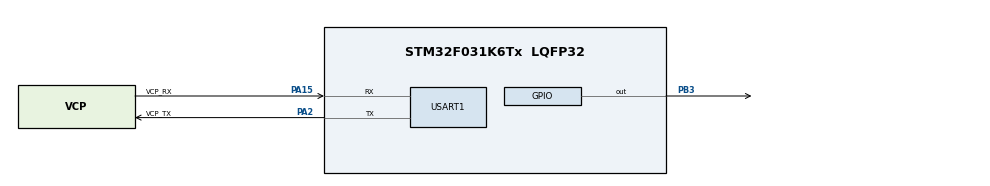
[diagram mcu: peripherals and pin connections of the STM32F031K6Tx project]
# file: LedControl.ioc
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Mcu.Family=STM32F0
Mcu.Name=STM32F031K6Tx
Mcu.Package=LQFP32
NVIC.USART1_IRQn=true\:0\:0\:false\:false\:true\:true\:true
PA13.GPIO_Label=SWDIO
PA13.Mode=Serial_Wire
PA13.Signal=SYS_SWDIO
PA14.GPIO_Label=SWCLK
PA14.Mode=Serial_Wire
PA14.Signal=SYS_SWCLK
PA15.GPIO_Label=VCP_RX
PA15.Mode=Asynchronous
PA15.Signal=USART1_RX
PA2.GPIO_Label=VCP_TX
PA2.Mode=Asynchronous
PA2.Signal=USART1_TX
PB3.Signal=GPIO_Output
PF0-OSC_IN.Mode=HSE-External-Clock-Source
PF0-OSC_IN.Signal=RCC_OSC_IN
ProjectManager.HeapSize=0x200
ProjectManager.StackSize=0x400
ProjectManager.TargetToolchain=MDK-ARM V5.27
USART1.VirtualMode-Asynchronous=VM_ASYNC
board=NUCLEO-F031K6

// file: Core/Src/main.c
/* USER CODE BEGIN Header */
/**
  ******************************************************************************
  * @file           : main.c
  * @brief          : Main program body
  ******************************************************************************
  * @attention
  *
  * <h2><center>&copy; Copyright (c) 2019 STMicroelectronics.
  * All rights reserved.</center></h2>
  *
  * This software component is licensed by ST under BSD 3-Clause license,
  * the "License"; You may not use this file except in compliance with the
  * License. You may obtain a copy of the License at:
  *                        opensource.org/licenses/BSD-3-Clause
  *
  ******************************************************************************
  */
/* USER CODE END Header */

#include "main.h"

UART_HandleTypeDef huart1;

void SystemClock_Config(void);
static void MX_GPIO_Init(void);
static void MX_USART1_UART_Init(void);

/* USER CODE BEGIN 0 */

typedef struct Node
{
	uint8_t Value;
	struct Node *Next;
} Node;

Node* head = NULL;
Node* curr = NULL;
int end = 0;

const char* MorzeCode[] =
{
	"13", //a
	"3111", //b
	"3131", //c
	"311", //d
	"1", //e
	"1131", //f
	"331", //g
	"1111", //h
	"11", //i
	"1333", //j
	"313", //k
	"1311", //l
	"33", // m
	"31", // n
	"333", // o
	"1331", //p
	"3313", //q
	"131", // r
	"111", //s
	"3", //t
	"113", //u
	"1113", //v
	"133", //w
	"3113", //x
	"3133", //y
	"3311", //z
};

int point = 400;

/*Node* DelayInc(Node* node, int delayX)
{
	HAL_Delay(point * delayX);
	return node->Next;
}*/

void GetLight(const char* code)
{
	for (int i = 0; code[i] != '\0'; i++, HAL_Delay(point))
	{
		HAL_GPIO_WritePin(GPIOB, GPIO_PIN_3, GPIO_PIN_SET);
		HAL_Delay(point * ((int)code[i] % 48));
		HAL_GPIO_WritePin(GPIOB, GPIO_PIN_3, GPIO_PIN_RESET);
	}
}

Node* newNode(uint8_t value)
{
	Node* node = (Node*) malloc(sizeof(Node));
	node->Value = value;
	node->Next = NULL;

	return node;
}
/* USER CODE END 0 */

int main(void)
{
  /* USER CODE BEGIN 1 */
	head = newNode(0);
	curr = head;

  /* USER CODE END 1 */

  /* MCU Configuration--------------------------------------------------------*/

  /* Reset of all peripherals, Initializes the Flash interface and the Systick. */
  HAL_Init();

  /* Configure the system clock */
  SystemClock_Config();

  /* Initialize all configured peripherals */
  MX_GPIO_Init();
  MX_USART1_UART_Init();

  /* USER CODE BEGIN 2 */
	HAL_Delay(5000);

	HAL_UART_Transmit(&huart1,
										(uint8_t*)"Enter a string. At the end write * \r\n",
										36,
										500000);

	HAL_UART_Receive_IT (&huart1, &(curr->Value), 1);
  /* USER CODE END 2 */

  /* Infinite loop */
  /* USER CODE BEGIN WHILE */
  while (1)
  {
		if (end == 1)
		{

			HAL_UART_Transmit(&huart1,
												(uint8_t*)"Morze encoding is going...\r\n",
												28,
												5000);

			Node* prev = head;

			for (Node* i = head;
					 i->Value != '*';
					 i = i->Next, HAL_Delay(point * 3), free(prev))
			{
				prev = i;
				HAL_UART_Transmit(&huart1, &(i->Value), 1, 5000);

				if ((i->Value == ' ') && (i != head))
				{
					HAL_Delay(4 * point);
					continue;
				}

				GetLight(MorzeCode[(int)(i->Value) % 97]);
			}

			HAL_UART_Transmit(&huart1,
												(uint8_t*)"\r\nThats all",
											  11,
												5000);
			end = 0;
		}
    /* USER CODE END WHILE */

  }
}

void HAL_UART_RxCpltCallback(UART_HandleTypeDef *huart)
{
  if(huart == &huart1)
	{
		if (curr->Value == '*')
		{
			end = 1;
			return;
		}

		curr->Next = newNode(0);
		curr = curr->Next;

		HAL_UART_Receive_IT(&huart1, &(curr->Value), 1);
  }
}

void HAL_UART_TxCpltCallback(UART_HandleTypeDef *huart)
{
	__NOP();
}
void SystemClock_Config(void)
{
  RCC_OscInitTypeDef RCC_OscInitStruct = {0};
  RCC_ClkInitTypeDef RCC_ClkInitStruct = {0};
  RCC_PeriphCLKInitTypeDef PeriphClkInit = {0};

  /** Initializes the CPU, AHB and APB busses clocks
  */
  RCC_OscInitStruct.OscillatorType = RCC_OSCILLATORTYPE_HSI;
  RCC_OscInitStruct.HSIState = RCC_HSI_ON;
  RCC_OscInitStruct.HSICalibrationValue = RCC_HSICALIBRATION_DEFAULT;
  RCC_OscInitStruct.PLL.PLLState = RCC_PLL_NONE;
  if (HAL_RCC_OscConfig(&RCC_OscInitStruct) != HAL_OK)
  {
    Error_Handler();
  }
  /** Initializes the CPU, AHB and APB busses clocks
  */
  RCC_ClkInitStruct.ClockType = RCC_CLOCKTYPE_HCLK|RCC_CLOCKTYPE_SYSCLK
                              |RCC_CLOCKTYPE_PCLK1;
  RCC_ClkInitStruct.SYSCLKSource = RCC_SYSCLKSOURCE_HSI;
  RCC_ClkInitStruct.AHBCLKDivider = RCC_SYSCLK_DIV1;
  RCC_ClkInitStruct.APB1CLKDivider = RCC_HCLK_DIV1;

  if (HAL_RCC_ClockConfig(&RCC_ClkInitStruct, FLASH_LATENCY_0) != HAL_OK)
  {
    Error_Handler();
  }
  PeriphClkInit.PeriphClockSelection = RCC_PERIPHCLK_USART1;
  PeriphClkInit.Usart1ClockSelection = RCC_USART1CLKSOURCE_PCLK1;
  if (HAL_RCCEx_PeriphCLKConfig(&PeriphClkInit) != HAL_OK)
  {
    Error_Handler();
  }
}

static void MX_USART1_UART_Init(void)
{

  huart1.Instance = USART1;
  huart1.Init.BaudRate = 38400;
  huart1.Init.WordLength = UART_WORDLENGTH_8B;
  huart1.Init.StopBits = UART_STOPBITS_1;
  huart1.Init.Parity = UART_PARITY_NONE;
  huart1.Init.Mode = UART_MODE_TX_RX;
  huart1.Init.HwFlowCtl = UART_HWCONTROL_NONE;
  huart1.Init.OverSampling = UART_OVERSAMPLING_16;
  huart1.Init.OneBitSampling = UART_ONE_BIT_SAMPLE_DISABLE;
  huart1.AdvancedInit.AdvFeatureInit = UART_ADVFEATURE_NO_INIT;
  if (HAL_UART_Init(&huart1) != HAL_OK)
  {
    Error_Handler();
  }

}

static void MX_GPIO_Init(void)
{
  GPIO_InitTypeDef GPIO_InitStruct = {0};

  /* GPIO Ports Clock Enable */
  __HAL_RCC_GPIOF_CLK_ENABLE();
  __HAL_RCC_GPIOA_CLK_ENABLE();
  __HAL_RCC_GPIOB_CLK_ENABLE();

  /*Configure GPIO pin Output Level */
  HAL_GPIO_WritePin(GPIOB, GPIO_PIN_3, GPIO_PIN_RESET);

  /*Configure GPIO pin : PB3 */
  GPIO_InitStruct.Pin = GPIO_PIN_3;
  GPIO_InitStruct.Mode = GPIO_MODE_OUTPUT_PP;
  GPIO_InitStruct.Pull = GPIO_NOPULL;
  GPIO_InitStruct.Speed = GPIO_SPEED_FREQ_LOW;
  HAL_GPIO_Init(GPIOB, &GPIO_InitStruct);

}

void Error_Handler(void)
{
}

/************************ (C) COPYRIGHT STMicroelectronics *****END OF FILE****/
